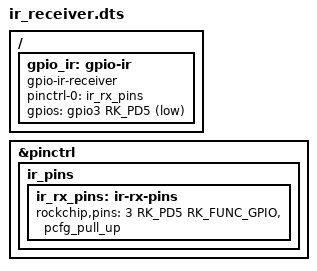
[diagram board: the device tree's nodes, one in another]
/dts-v1/;
/plugin/;

#include <dt-bindings/gpio/gpio.h>
#include <dt-bindings/pinctrl/rockchip.h>

/ {
	fragment@0 {
		target = <&pinctrl>;
		__overlay__ {
			ir_pins {
				ir_rx_pins: ir-rx-pins {
					rockchip,pins = <3 RK_PD5 RK_FUNC_GPIO &pcfg_pull_up>;	// PIN# 13, pull-up
				};
			};
		};
	};
	fragment@1 {
		target-path = "/";
		__overlay__ {
			gpio_ir: gpio-ir {
				status = "okay";
				compatible = "gpio-ir-receiver";
				pinctrl-names = "default";
				pinctrl-0 = <&ir_rx_pins>;
				gpios = <&gpio3 RK_PD5 GPIO_ACTIVE_LOW>;	// PIN# 13
			};
		};
	};
};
